# u_cyber_otpm: IP-XACT component
VLNV spiritconsortium.org:uvm_reg_ex:u_cyber_otpm:1685-2009

## Address spaces and blocks
otpm_map.crypto_otpm: base 0x0000, range 0x0037, width 32

## Registers
Registers are 32-bit, read-write, reset 0x0 unless marked. A register's access mark holds for its fields unless they carry their own. Offsets are from the block's base; lines under a group give offsets from that group; [hi:lo] are bit positions; {n}, {i} and the like mark numbered series; 'fields as' and 'values as' point back to an identical list; <NAME> marks a mode.

## otpm_map.crypto_otpm
Base 0x00000000
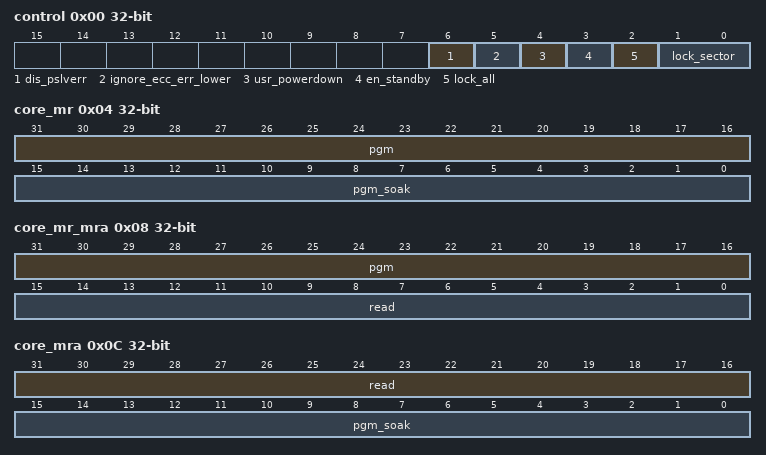
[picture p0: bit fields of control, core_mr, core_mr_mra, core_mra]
0x00 control
  [6] dis_pslverr, [5] ignore_ecc_err_lower, [4] usr_powerdown, [3] en_standby, [2] lock_all, [1:0] lock_sector
0x04 core_mr
  [31:16] pgm, [15:0] pgm_soak
0x08 core_mr_mra
  [31:16] pgm, [15:0] read
0x0C core_mra
  [31:16] read, [15:0] pgm_soak
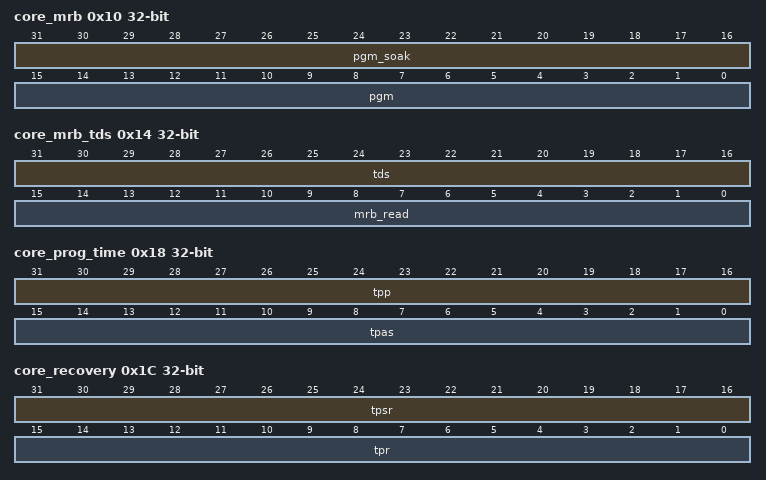
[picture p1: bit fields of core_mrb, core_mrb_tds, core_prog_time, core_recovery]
0x10 core_mrb
  [31:16] pgm_soak, [15:0] pgm
0x14 core_mrb_tds
  [31:16] tds, [15:0] mrb_read
0x18 core_prog_time
  [31:16] tpp, [15:0] tpas
0x1C core_recovery
  [31:16] tpsr, [15:0] tpr
0x20 core_soak_cycles
  [31:0] tspp
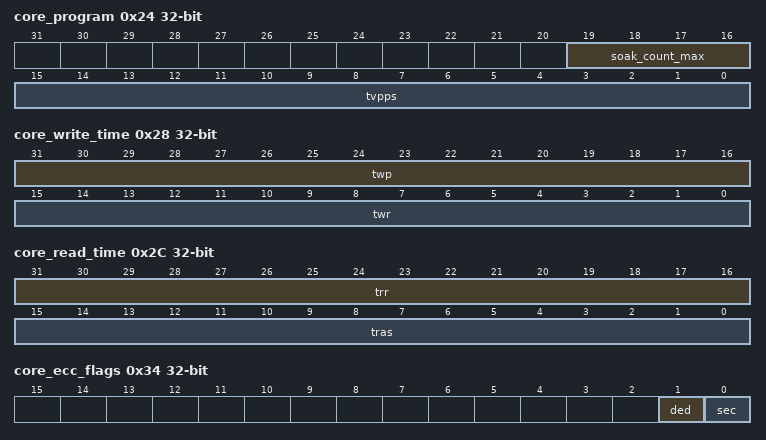
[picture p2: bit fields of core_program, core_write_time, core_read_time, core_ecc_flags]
0x24 core_program
  [19:16] soak_count_max, [15:0] tvpps
0x28 core_write_time
  [31:16] twp, [15:0] twr
0x2C core_read_time
  [31:16] trr, [15:0] tras
0x30 core_read_error
  [15:0] address
0x34 core_ecc_flags
  [1] ded, [0] sec
